AUTOSAR XML (schema 4.0)
standard types defined: float32, float64, sint16, sint32, sint8, uint16, uint32, uint8, void, boolean
package /ImplDataTypes
  8 x impl type, all with category=TYPE_REFERENCE, type-emitter=RTE:
    IoPositionSensorReadingType: implementation-data-type=uint8
    IoWeightSensorReadingType: implementation-data-type=uint16
    MultiStateBtnType: implementation-data-type=uint8
    SeatCtrlDataType: implementation-data-type=uint8
    SeatModeBtnType: implementation-data-type=uint8
    SensorPositionType: implementation-data-type=uint8
    SensorWeightType: implementation-data-type=uint8
    StepMotorStepType: implementation-data-type=uint8
package /MappingSets
  data type mapping set MappingSet: mode-request-type-map{implementation-data-type=uint8, mode-group=SeatCtrlMode}
package /PortInterfaces/ClientServer
  6 x client server interface:
    CsIf_IoGetSensorPosition
      operation IoGet
        arg position: type=IoPositionSensorReadingType, direction=IN
    CsIf_IoGetSensorWeight
      operation IoGet
        arg weight: type=IoWeightSensorReadingType, direction=IN
    CsIf_IoSetMotor
      operation IoSetForward
      operation IoSetReverse
    CsIf_PositionSensor
      operation GetPosition
        arg position: type=SensorPositionType, direction=IN
    CsIf_StepMotor
      operation Move
        arg step: type=StepMotorStepType, direction=IN
    CsIf_WeightSensor
      operation GetWeight
        arg weight: type=MultiStateBtnType, direction=IN
package /PortInterfaces/ModeSwitch
  mode switch interface MsIf_SeatCtrlMode
    mode group SeatCtrlMode: type=SeatCtrlMode
  mode declaration group SeatCtrlMode: category=ALPHABETIC_ORDER, initial-mode=INIT, on-transition-value=255
    mode AUTO
    mode INIT
    mode MANUAL
package /PortInterfaces/SenderReceiver
  sender receiver interface SrIf_SeatCtrlBtns
    data DE_HeightBtnState: type=MultiStateBtnType
    data DE_InclineBtnState: type=MultiStateBtnType
    data DE_SlideBtnState: type=MultiStateBtnType
  sender receiver interface SrIf_SeatCtrlData
    data DE_Height: type=SeatCtrlDataType
    data DE_Incline: type=SeatCtrlDataType
    data DE_Slide: type=SeatCtrlDataType
  sender receiver interface SrIf_SeatModeBtn
    data SeatModeBtn: type=SeatModeBtnType
package /SoftwareComponents
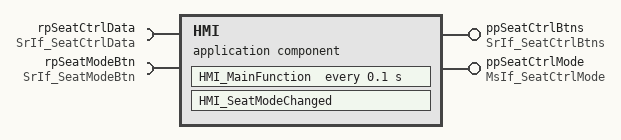
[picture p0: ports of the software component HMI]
  application sw component type HMI
    provide port ppSeatCtrlBtns: provided-interface=SrIf_SeatCtrlBtns
    provide port ppSeatCtrlMode: provided-interface=MsIf_SeatCtrlMode
    require port rpSeatCtrlData: required-interface=SrIf_SeatCtrlData
    require port rpSeatModeBtn: required-interface=SrIf_SeatModeBtn
    behavior Ibhv_HMI: data-type-mapping=MappingSet, handle-termination-and-restart=NO-SUPPORT
      data received event DRE_rpSeatModeBtn_SeatModeBtn: start-on-event=HMI_SeatModeChanged, data=rpSeatModeBtn.SeatModeBtn
      timing event TE_HMI_MainFunction_100ms: start-on-event=HMI_MainFunction, period=0.1
      runnable HMI_MainFunction
        data-receive-point-by-arguments:
          access DRP_rpSeatCtrlData_DE_Height: accessed-variable=rpSeatCtrlData.DE_Height
          access DRP_rpSeatCtrlData_DE_Incline: accessed-variable=rpSeatCtrlData.DE_Incline
          access DRP_rpSeatCtrlData_DE_Slide: accessed-variable=rpSeatCtrlData.DE_Slide
        data-send-points:
          access DSP_ppSeatCtrlBtns_DE_HeightBtnState: accessed-variable=ppSeatCtrlBtns.DE_HeightBtnState
          access DSP_ppSeatCtrlBtns_DE_InclineBtnState: accessed-variable=ppSeatCtrlBtns.DE_InclineBtnState
          access DSP_ppSeatCtrlBtns_DE_SlideBtnState: accessed-variable=ppSeatCtrlBtns.DE_SlideBtnState
      runnable HMI_SeatModeChanged
        data-receive-point-by-arguments:
          access DRP_rpSeatModeBtn_SeatModeBtn: accessed-variable=rpSeatModeBtn.SeatModeBtn
        mode switch point MSP_ppSeatCtrlMode_ppSeatCtrlMode: mode-group=ppSeatCtrlMode.SeatCtrlMode
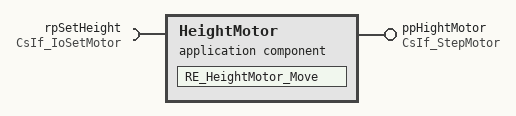
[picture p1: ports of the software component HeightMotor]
  application sw component type HeightMotor
    provide port ppHightMotor: provided-interface=CsIf_StepMotor
    require port rpSetHeight: required-interface=CsIf_IoSetMotor
    behavior Ibhv_HeightMotor: data-type-mapping=MappingSet, handle-termination-and-restart=NO-SUPPORT
      operation invoked event OIE_ppHightMotor_Move: start-on-event=RE_HeightMotor_Move, operation=ppHightMotor.Move
      runnable RE_HeightMotor_Move
        sync call SCP_rpSetHeight_IoSetForward: operation=rpSetHeight.IoSetForward, timeout=0.0
        sync call SCP_rpSetHeight_IoSetReverse: operation=rpSetHeight.IoSetReverse, timeout=0.0
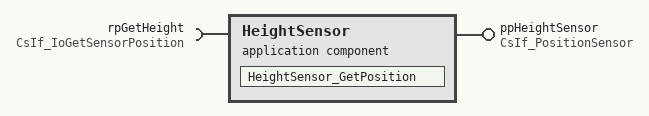
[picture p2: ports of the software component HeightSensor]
  application sw component type HeightSensor
    provide port ppHeightSensor: provided-interface=CsIf_PositionSensor
    require port rpGetHeight: required-interface=CsIf_IoGetSensorPosition
    behavior Ibhv_HeightSensor: data-type-mapping=MappingSet, handle-termination-and-restart=NO-SUPPORT
      operation invoked event OIE_ppHeightSensor_GetPosition: start-on-event=HeightSensor_GetPosition, operation=ppHeightSensor.GetPosition
      runnable HeightSensor_GetPosition
        sync call SCP_rpGetHeight_IoGet: operation=rpGetHeight.IoGet, timeout=0.0
  10 x swc implementation, all with programming-language=C, sw-version=1.0.0, vendor-id=255:
    Impl_HMI: behavior=Ibhv_HMI
      code-descriptors:
        code Code: artifact-descriptors=autosar-engineering-object={short-label=SWC.c, category=SWSRC}
      resource consumption ResourceConsumption
    Impl_HeightMotor: behavior=Ibhv_HeightMotor
      code-descriptors:
        code Code: artifact-descriptors=autosar-engineering-object={short-label=SWC.c, category=SWSRC}
      resource consumption ResourceConsumption
    Impl_HeightSensor: behavior=Ibhv_HeightSensor
      code-descriptors:
        code Code: artifact-descriptors=autosar-engineering-object={short-label=SWC.c, category=SWSRC}
      resource consumption ResourceConsumption
    Impl_InclineMotor: behavior=Ibhv_InclineMotor
      code-descriptors:
        code Code: artifact-descriptors=autosar-engineering-object={short-label=SWC.c, category=SWSRC}
      resource consumption ResourceConsumption
    Impl_InclineSensor: behavior=Ibhv_InclineSensor
      code-descriptors:
        code Code: artifact-descriptors=autosar-engineering-object={short-label=SWC.c, category=SWSRC}
      resource consumption ResourceConsumption
    Impl_IoHwAbs: behavior=Ibhv_IoHwAbs
      code-descriptors:
        code Code: artifact-descriptors=autosar-engineering-object={short-label=SWC.c, category=SWSRC}
      resource consumption ResourceConsumption
    Impl_SeatMgr: behavior=Ibhv_SeatMgr
      code-descriptors:
        code Code: artifact-descriptors=autosar-engineering-object={short-label=SWC.c, category=SWSRC}
      resource consumption ResourceConsumption
    Impl_SlideMotor: behavior=Ibhv_SlideMotor
      code-descriptors:
        code Code: artifact-descriptors=autosar-engineering-object={short-label=SWC.c, category=SWSRC}
      resource consumption ResourceConsumption
    Impl_SlideSensor: behavior=Ibhv_SlideSensor
      code-descriptors:
        code Code: artifact-descriptors=autosar-engineering-object={short-label=SWC.c, category=SWSRC}
      resource consumption ResourceConsumption
    Impl_WeightSensor: behavior=Ibhv_WeightSensor
      code-descriptors:
        code Code: artifact-descriptors=autosar-engineering-object={short-label=SWC.c, category=SWSRC}
      resource consumption ResourceConsumption
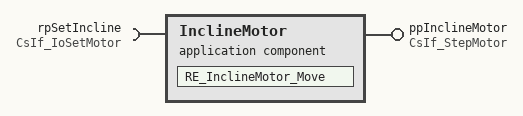
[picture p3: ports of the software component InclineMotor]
  application sw component type InclineMotor
    provide port ppInclineMotor: provided-interface=CsIf_StepMotor
    require port rpSetIncline: required-interface=CsIf_IoSetMotor
    behavior Ibhv_InclineMotor: data-type-mapping=MappingSet, handle-termination-and-restart=NO-SUPPORT
      operation invoked event OIE_ppInclineMotor_Move: start-on-event=RE_InclineMotor_Move, operation=ppInclineMotor.Move
      runnable RE_InclineMotor_Move
        sync call SCP_rpSetIncline_IoSetForward: operation=rpSetIncline.IoSetForward, timeout=0.0
        sync call SCP_rpSetIncline_IoSetReverse: operation=rpSetIncline.IoSetReverse, timeout=0.0
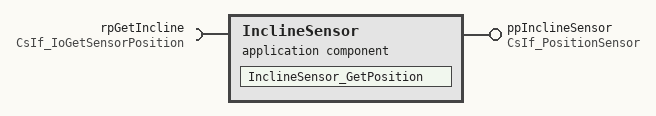
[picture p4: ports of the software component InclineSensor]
  application sw component type InclineSensor
    provide port ppInclineSensor: provided-interface=CsIf_PositionSensor
    require port rpGetIncline: required-interface=CsIf_IoGetSensorPosition
    behavior Ibhv_InclineSensor: data-type-mapping=MappingSet, handle-termination-and-restart=NO-SUPPORT
      operation invoked event OIE_ppInclineSensor_GetPosition: start-on-event=InclineSensor_GetPosition, operation=ppInclineSensor.GetPosition
      runnable InclineSensor_GetPosition
        sync call SCP_rpGetIncline_IoGet: operation=rpGetIncline.IoGet, timeout=0.0
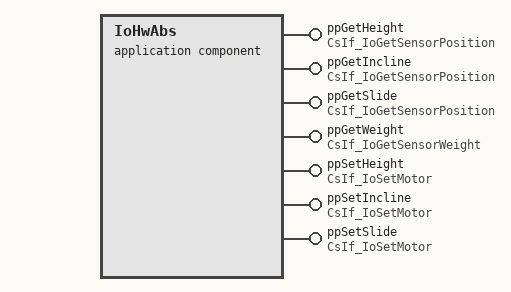
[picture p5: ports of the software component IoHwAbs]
  application sw component type IoHwAbs
    7 x provide port:
      ppGetHeight: provided-interface=CsIf_IoGetSensorPosition
      ppGetIncline: provided-interface=CsIf_IoGetSensorPosition
      ppGetSlide: provided-interface=CsIf_IoGetSensorPosition
      ppGetWeight: provided-interface=CsIf_IoGetSensorWeight
      ppSetHeight: provided-interface=CsIf_IoSetMotor
      ppSetIncline: provided-interface=CsIf_IoSetMotor
      ppSetSlide: provided-interface=CsIf_IoSetMotor
    behavior Ibhv_IoHwAbs: data-type-mapping=MappingSet, handle-termination-and-restart=NO-SUPPORT
      10 x operation invoked event:
        OIE_ppGetHeight_IoGet: start-on-event=IoHwAbs_ECUGet_Height, operation=ppGetHeight.IoGet
        OIE_ppGetIncline_IoGet: start-on-event=IoHwAbs_ECUGet_Incline, operation=ppGetIncline.IoGet
        OIE_ppGetSlide_IoGet: start-on-event=IoHwAbs_ECUGet_Slide, operation=ppGetSlide.IoGet
        OIE_ppGetWeight_IoGet: start-on-event=IoHwAbs_ECUGet_Weight, operation=ppGetWeight.IoGet
        OIE_ppSetHeight_IoSetForward: start-on-event=IoHwAbs_ECUSetForward_Height, operation=ppSetHeight.IoSetForward
        OIE_ppSetHeight_IoSetReverse: start-on-event=IoHwAbs_ECUSetReverse_Height, operation=ppSetHeight.IoSetReverse
        OIE_ppSetIncline_IoSetForward: start-on-event=IoHwAbs_ECUSetForward_Incline, operation=ppSetIncline.IoSetForward
        OIE_ppSetIncline_IoSetReverse: start-on-event=IoHwAbs_ECUSetReverse_Incline, operation=ppSetIncline.IoSetReverse
        OIE_ppSetSlide_IoSetForward: start-on-event=IoHwAbs_ECUSetForward_Slide, operation=ppSetSlide.IoSetForward
        OIE_ppSetSlide_IoSetReverse: start-on-event=IoHwAbs_ECUSetReverse_slide, operation=ppSetSlide.IoSetReverse
      10 x runnable:
        IoHwAbs_ECUGet_Height
        IoHwAbs_ECUGet_Incline
        IoHwAbs_ECUGet_Slide
        IoHwAbs_ECUGet_Weight
        IoHwAbs_ECUSetForward_Height
        IoHwAbs_ECUSetForward_Incline
        IoHwAbs_ECUSetForward_Slide
        IoHwAbs_ECUSetReverse_Height
        IoHwAbs_ECUSetReverse_Incline
        IoHwAbs_ECUSetReverse_slide
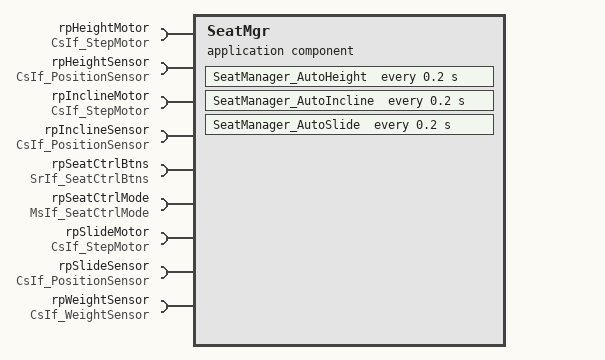
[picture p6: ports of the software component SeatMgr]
  application sw component type SeatMgr
    9 x require port:
      rpHeightMotor: required-interface=CsIf_StepMotor
      rpHeightSensor: required-interface=CsIf_PositionSensor
      rpInclineMotor: required-interface=CsIf_StepMotor
      rpInclineSensor: required-interface=CsIf_PositionSensor
      rpSeatCtrlBtns: required-interface=SrIf_SeatCtrlBtns
      rpSeatCtrlMode: required-interface=MsIf_SeatCtrlMode
      rpSlideMotor: required-interface=CsIf_StepMotor
      rpSlideSensor: required-interface=CsIf_PositionSensor
      rpWeightSensor: required-interface=CsIf_WeightSensor
    behavior Ibhv_SeatMgr: data-type-mapping=MappingSet, handle-termination-and-restart=NO-SUPPORT
      data received event DRE_rpSeatCtrlBtns_DE_HeightBtnState: start-on-event=Seatmanager_SetHight, data=rpSeatCtrlBtns.DE_HeightBtnState
      data received event DRE_rpSeatCtrlBtns_DE_InclineBtnState: start-on-event=Seatmanager_SetIncline, data=rpSeatCtrlBtns.DE_InclineBtnState
      data received event DRE_rpSeatCtrlBtns_DE_SlideBtnState: start-on-event=Seatmanager_SetSlide, data=rpSeatCtrlBtns.DE_SlideBtnState
      timing event TE_SeatManager_AutoHeight_200ms: start-on-event=SeatManager_AutoHeight, period=0.2
      timing event TE_SeatManager_AutoIncline_200ms: start-on-event=SeatManager_AutoIncline, period=0.2
      timing event TE_SeatManager_AutoSlide_200ms: start-on-event=SeatManager_AutoSlide, period=0.2
      6 x runnable:
        SeatManager_AutoHeight
          sync call SCP_rpHeightMotor_Move: operation=rpHeightMotor.Move, timeout=0.0
          sync call SCP_rpHeightSensor_GetPosition: operation=rpHeightSensor.GetPosition, timeout=0.0
          sync call SCP_rpWeightSensor_GetWeight: operation=rpWeightSensor.GetWeight, timeout=0.0
        SeatManager_AutoIncline
          sync call SCP_rpInclineMotor_Move: operation=rpInclineMotor.Move, timeout=0.0
          sync call SCP_rpInclineSensor_GetPosition: operation=rpInclineSensor.GetPosition, timeout=0.0
          sync call SCP_rpWeightSensor_GetWeight: operation=rpWeightSensor.GetWeight, timeout=0.0
        SeatManager_AutoSlide
          sync call SCP_rpSlideMotor_Move: operation=rpSlideMotor.Move, timeout=0.0
          sync call SCP_rpSlideSensor_GetPosition: operation=rpSlideSensor.GetPosition, timeout=0.0
          sync call SCP_rpWeightSensor_GetWeight: operation=rpWeightSensor.GetWeight, timeout=0.0
        Seatmanager_SetHight
          sync call SCP_rp_HeightMotor_Move: operation=rpHeightMotor.Move, timeout=0.0
        Seatmanager_SetIncline
          sync call SCP_rp_InclineMotor_Move: operation=rpInclineMotor.Move, timeout=0.0
        Seatmanager_SetSlide
          sync call SCP_rp_SlideMotor_Move: operation=rpSlideMotor.Move, timeout=0.0
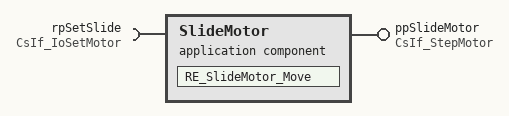
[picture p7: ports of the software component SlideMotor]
  application sw component type SlideMotor
    provide port ppSlideMotor: provided-interface=CsIf_StepMotor
    require port rpSetSlide: required-interface=CsIf_IoSetMotor
    behavior Ibhv_SlideMotor: data-type-mapping=MappingSet, handle-termination-and-restart=NO-SUPPORT
      operation invoked event OIE_ppSlideMotor_Move: start-on-event=RE_SlideMotor_Move, operation=ppSlideMotor.Move
      runnable RE_SlideMotor_Move
        sync call SCP_rpSetSlide_IoSetForward: operation=rpSetSlide.IoSetForward, timeout=0.0
        sync call SCP_rpSetSlide_IoSetReverse: operation=rpSetSlide.IoSetReverse, timeout=0.0
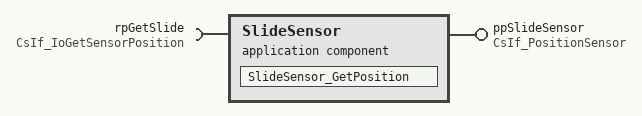
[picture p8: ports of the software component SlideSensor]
  application sw component type SlideSensor
    provide port ppSlideSensor: provided-interface=CsIf_PositionSensor
    require port rpGetSlide: required-interface=CsIf_IoGetSensorPosition
    behavior Ibhv_SlideSensor: data-type-mapping=MappingSet, handle-termination-and-restart=NO-SUPPORT
      operation invoked event OIE_ppSlideSensor_GetPosition: start-on-event=SlideSensor_GetPosition, operation=ppSlideSensor.GetPosition
      runnable SlideSensor_GetPosition
        sync call SCP_rpGetSlide_IoGet: operation=rpGetSlide.IoGet, timeout=0.0
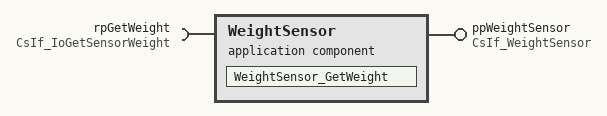
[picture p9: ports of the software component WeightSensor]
  application sw component type WeightSensor
    provide port ppWeightSensor: provided-interface=CsIf_WeightSensor
    require port rpGetWeight: required-interface=CsIf_IoGetSensorWeight
    behavior Ibhv_WeightSensor: data-type-mapping=MappingSet, handle-termination-and-restart=NO-SUPPORT
      operation invoked event OIE_ppWeightSensor_GetWeight: start-on-event=WeightSensor_GetWeight, operation=ppWeightSensor.GetWeight
      runnable WeightSensor_GetWeight
        sync call SCP_rpGetWeight_IoGet: operation=rpGetWeight.IoGet, timeout=0.0
package /Compositions
  composition sw component type SR_comm_task2Composition
    10 x component:
      HMI: type=HMI
      HeightMotor: type=HeightMotor
      HeightSensor: type=HeightSensor
      InclineMotor: type=InclineMotor
      InclineSensor: type=InclineSensor
      IoHwAbs: type=IoHwAbs
      SeatMgr: type=SeatMgr
      SlideMotor: type=SlideMotor
      SlideSensor: type=SlideSensor
      WeightSensor: type=WeightSensor
    connect HMI.ppSeatCtrlBtns -> SeatMgr.rpSeatCtrlBtns
    connect HMI.ppSeatCtrlMode -> SeatMgr.rpSeatCtrlMode
    connect HeightMotor.ppHightMotor -> SeatMgr.rpHeightMotor
    connect HeightSensor.ppHeightSensor -> SeatMgr.rpHeightSensor
    connect InclineMotor.ppInclineMotor -> SeatMgr.rpInclineMotor
    connect InclineSensor.ppInclineSensor -> SeatMgr.rpInclineSensor
    connect IoHwAbs.ppGetHeight -> HeightSensor.rpGetHeight
    connect IoHwAbs.ppGetIncline -> InclineSensor.rpGetIncline
    connect IoHwAbs.ppGetSlide -> SlideSensor.rpGetSlide
    connect IoHwAbs.ppGetWeight -> WeightSensor.rpGetWeight
    connect IoHwAbs.ppSetHeight -> HeightMotor.rpSetHeight
    connect IoHwAbs.ppSetIncline -> InclineMotor.rpSetIncline
    connect IoHwAbs.ppSetSlide -> SlideMotor.rpSetSlide
    connect SlideMotor.ppSlideMotor -> SeatMgr.rpSlideMotor
    connect SlideSensor.ppSlideSensor -> SeatMgr.rpSlideSensor
    connect WeightSensor.ppWeightSensor -> SeatMgr.rpWeightSensor
